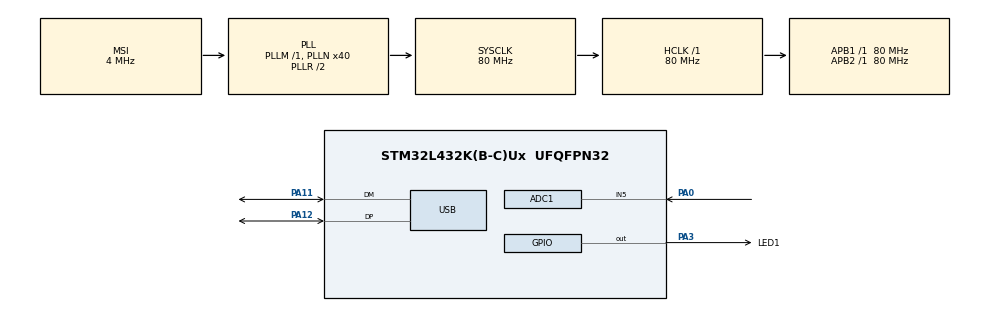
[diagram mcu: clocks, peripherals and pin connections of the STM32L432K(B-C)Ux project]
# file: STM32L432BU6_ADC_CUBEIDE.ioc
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ADC1.Channel-0\#ChannelRegularConversion=ADC_CHANNEL_5
ADC1.NbrOfConversionFlag=1
ADC1.master=1
Mcu.Family=STM32L4
Mcu.Name=STM32L432K(B-C)Ux
Mcu.Package=UFQFPN32
NVIC.PriorityGroup=NVIC_PRIORITYGROUP_4
NVIC.USB_IRQn=true\:0\:0\:false\:false\:true\:false\:true\:true
PA0.Signal=ADCx_IN5
PA11.Mode=Device
PA11.Signal=USB_DM
PA12.Mode=Device
PA12.Signal=USB_DP
PA13\ (JTMS-SWDIO).Mode=Serial_Wire
PA13\ (JTMS-SWDIO).Signal=SYS_JTMS-SWDIO
PA14\ (JTCK-SWCLK).Mode=Serial_Wire
PA14\ (JTCK-SWCLK).Signal=SYS_JTCK-SWCLK
PA3.GPIO_Label=LED1
PA3.Signal=GPIO_Output
ProjectManager.HeapSize=0x200
ProjectManager.StackSize=0x400
ProjectManager.TargetToolchain=STM32CubeIDE
RCC.ADCFreq_Value=48000000
RCC.AHBFreq_Value=80000000
RCC.APB1Freq_Value=80000000
RCC.APB1TimFreq_Value=80000000
RCC.APB2Freq_Value=80000000
RCC.APB2TimFreq_Value=80000000
RCC.CortexFreq_Value=80000000
RCC.HCLKFreq_Value=80000000
RCC.HSE_VALUE=8000000
RCC.HSI48_VALUE=48000000
RCC.HSI_VALUE=16000000
RCC.LSE_VALUE=32768
RCC.MSI_VALUE=4000000
RCC.PLLN=40
RCC.PLLSAI1N=24
RCC.SYSCLKFreq_VALUE=80000000
RCC.SYSCLKSource=RCC_SYSCLKSOURCE_PLLCLK
RCC.USBFreq_Value=48000000
RCC.VCOOutputFreq_Value=160000000
SH.ADCx_IN5.0=ADC1_IN5,IN5-Single-Ended
USB_DEVICE.CLASS_NAME_FS=CDC
USB_DEVICE.VirtualMode=Cdc
USB_DEVICE.VirtualModeFS=Cdc_FS
VP_USB_DEVICE_VS_USB_DEVICE_CDC_FS.Mode=CDC_FS
board=custom

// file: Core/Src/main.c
/* USER CODE BEGIN Header */
/**
  ******************************************************************************
  * @file           : main.c
  * @brief          : Main program body
  ******************************************************************************
  * @attention
  *
  * Copyright (c) 2024 STMicroelectronics.
  * All rights reserved.
  *
  * This software is licensed under terms that can be found in the LICENSE file
  * in the root directory of this software component.
  * If no LICENSE file comes with this software, it is provided AS-IS.
  *
  ******************************************************************************
  */
/* USER CODE END Header */
#include "main.h"
#include "usb_device.h"

/* USER CODE BEGIN Includes */
#include "usbd_cdc_if.h"
#include "string.h"
/* USER CODE END Includes */

ADC_HandleTypeDef hadc1;

void SystemClock_Config(void);
void PeriphCommonClock_Config(void);
static void MX_GPIO_Init(void);
static void MX_ADC1_Init(void);

int main(void)
{
  /* USER CODE BEGIN 1 */
	uint16_t raw;
	char msg[10];
  /* USER CODE END 1 */

  /* MCU Configuration--------------------------------------------------------*/

  /* Reset of all peripherals, Initializes the Flash interface and the Systick. */
  HAL_Init();

  /* Configure the system clock */
  SystemClock_Config();

/* Configure the peripherals common clocks */
  PeriphCommonClock_Config();

  /* Initialize all configured peripherals */
  MX_GPIO_Init();
  MX_ADC1_Init();
  MX_USB_DEVICE_Init();

  /* Infinite loop */
  /* USER CODE BEGIN WHILE */
  while (1)
  {

	  HAL_ADC_Start(&hadc1);
	  HAL_ADC_PollForConversion(&hadc1, HAL_MAX_DELAY);
	  raw = HAL_ADC_GetValue(&hadc1);

	  sprintf(msg, "%hu\r\n", raw);
	  CDC_Transmit_FS((uint8_t *) msg, strlen(msg));
	  HAL_Delay(1000);
    /* USER CODE END WHILE */

  }
}

void SystemClock_Config(void)
{
  RCC_OscInitTypeDef RCC_OscInitStruct = {0};
  RCC_ClkInitTypeDef RCC_ClkInitStruct = {0};

  /** Configure the main internal regulator output voltage
  */
  if (HAL_PWREx_ControlVoltageScaling(PWR_REGULATOR_VOLTAGE_SCALE1) != HAL_OK)
  {
    Error_Handler();
  }

  /** Initializes the RCC Oscillators according to the specified parameters
  * in the RCC_OscInitTypeDef structure.
  */
  RCC_OscInitStruct.OscillatorType = RCC_OSCILLATORTYPE_MSI;
  RCC_OscInitStruct.MSIState = RCC_MSI_ON;
  RCC_OscInitStruct.MSICalibrationValue = 0;
  RCC_OscInitStruct.MSIClockRange = RCC_MSIRANGE_6;
  RCC_OscInitStruct.PLL.PLLState = RCC_PLL_ON;
  RCC_OscInitStruct.PLL.PLLSource = RCC_PLLSOURCE_MSI;
  RCC_OscInitStruct.PLL.PLLM = 1;
  RCC_OscInitStruct.PLL.PLLN = 40;
  RCC_OscInitStruct.PLL.PLLP = RCC_PLLP_DIV7;
  RCC_OscInitStruct.PLL.PLLQ = RCC_PLLQ_DIV2;
  RCC_OscInitStruct.PLL.PLLR = RCC_PLLR_DIV2;
  if (HAL_RCC_OscConfig(&RCC_OscInitStruct) != HAL_OK)
  {
    Error_Handler();
  }

  /** Initializes the CPU, AHB and APB buses clocks
  */
  RCC_ClkInitStruct.ClockType = RCC_CLOCKTYPE_HCLK|RCC_CLOCKTYPE_SYSCLK
                              |RCC_CLOCKTYPE_PCLK1|RCC_CLOCKTYPE_PCLK2;
  RCC_ClkInitStruct.SYSCLKSource = RCC_SYSCLKSOURCE_PLLCLK;
  RCC_ClkInitStruct.AHBCLKDivider = RCC_SYSCLK_DIV1;
  RCC_ClkInitStruct.APB1CLKDivider = RCC_HCLK_DIV1;
  RCC_ClkInitStruct.APB2CLKDivider = RCC_HCLK_DIV1;

  if (HAL_RCC_ClockConfig(&RCC_ClkInitStruct, FLASH_LATENCY_4) != HAL_OK)
  {
    Error_Handler();
  }
}

void PeriphCommonClock_Config(void)
{
  RCC_PeriphCLKInitTypeDef PeriphClkInit = {0};

  /** Initializes the peripherals clock
  */
  PeriphClkInit.PeriphClockSelection = RCC_PERIPHCLK_USB|RCC_PERIPHCLK_ADC;
  PeriphClkInit.AdcClockSelection = RCC_ADCCLKSOURCE_PLLSAI1;
  PeriphClkInit.UsbClockSelection = RCC_USBCLKSOURCE_PLLSAI1;
  PeriphClkInit.PLLSAI1.PLLSAI1Source = RCC_PLLSOURCE_MSI;
  PeriphClkInit.PLLSAI1.PLLSAI1M = 1;
  PeriphClkInit.PLLSAI1.PLLSAI1N = 24;
  PeriphClkInit.PLLSAI1.PLLSAI1P = RCC_PLLP_DIV7;
  PeriphClkInit.PLLSAI1.PLLSAI1Q = RCC_PLLQ_DIV2;
  PeriphClkInit.PLLSAI1.PLLSAI1R = RCC_PLLR_DIV2;
  PeriphClkInit.PLLSAI1.PLLSAI1ClockOut = RCC_PLLSAI1_48M2CLK|RCC_PLLSAI1_ADC1CLK;
  if (HAL_RCCEx_PeriphCLKConfig(&PeriphClkInit) != HAL_OK)
  {
    Error_Handler();
  }
}

static void MX_ADC1_Init(void)
{

  ADC_ChannelConfTypeDef sConfig = {0};

  /** Common config
  */
  hadc1.Instance = ADC1;
  hadc1.Init.ClockPrescaler = ADC_CLOCK_ASYNC_DIV1;
  hadc1.Init.Resolution = ADC_RESOLUTION_12B;
  hadc1.Init.DataAlign = ADC_DATAALIGN_RIGHT;
  hadc1.Init.ScanConvMode = ADC_SCAN_DISABLE;
  hadc1.Init.EOCSelection = ADC_EOC_SINGLE_CONV;
  hadc1.Init.LowPowerAutoWait = DISABLE;
  hadc1.Init.ContinuousConvMode = DISABLE;
  hadc1.Init.NbrOfConversion = 1;
  hadc1.Init.DiscontinuousConvMode = DISABLE;
  hadc1.Init.ExternalTrigConv = ADC_SOFTWARE_START;
  hadc1.Init.ExternalTrigConvEdge = ADC_EXTERNALTRIGCONVEDGE_NONE;
  hadc1.Init.DMAContinuousRequests = DISABLE;
  hadc1.Init.Overrun = ADC_OVR_DATA_PRESERVED;
  hadc1.Init.OversamplingMode = DISABLE;
  if (HAL_ADC_Init(&hadc1) != HAL_OK)
  {
    Error_Handler();
  }

  /** Configure Regular Channel
  */
  sConfig.Channel = ADC_CHANNEL_5;
  sConfig.Rank = ADC_REGULAR_RANK_1;
  sConfig.SamplingTime = ADC_SAMPLETIME_2CYCLES_5;
  sConfig.SingleDiff = ADC_SINGLE_ENDED;
  sConfig.OffsetNumber = ADC_OFFSET_NONE;
  sConfig.Offset = 0;
  if (HAL_ADC_ConfigChannel(&hadc1, &sConfig) != HAL_OK)
  {
    Error_Handler();
  }

}

static void MX_GPIO_Init(void)
{
  GPIO_InitTypeDef GPIO_InitStruct = {0};

  /* GPIO Ports Clock Enable */
  __HAL_RCC_GPIOA_CLK_ENABLE();

  /*Configure GPIO pin Output Level */
  HAL_GPIO_WritePin(LED1_GPIO_Port, LED1_Pin, GPIO_PIN_RESET);

  /*Configure GPIO pin : LED1_Pin */
  GPIO_InitStruct.Pin = LED1_Pin;
  GPIO_InitStruct.Mode = GPIO_MODE_OUTPUT_PP;
  GPIO_InitStruct.Pull = GPIO_NOPULL;
  GPIO_InitStruct.Speed = GPIO_SPEED_FREQ_LOW;
  HAL_GPIO_Init(LED1_GPIO_Port, &GPIO_InitStruct);

}

/* USER CODE BEGIN 4 */
void HAL_ADC_ConvCpltCallback(ADC_HandleTypeDef* hadc)
{
	HAL_GPIO_WritePin(LED1_GPIO_Port, LED1_Pin, GPIO_PIN_SET);

}

void HAL_ADC_ConvHalfCpltCallback(ADC_HandleTypeDef* hadc)
{
	HAL_GPIO_WritePin(LED1_GPIO_Port, LED1_Pin, GPIO_PIN_RESET);
}

/* USER CODE END 4 */

void Error_Handler(void)
{
  __disable_irq();
  while (1)
  {
  }
}
